# nrf9230_cellcore register map
Vendor: Nordic Semiconductor; Series: nRF92; File version: 1
CPU: CM33 r0p4, little endian, MPU, FPU, 3 interrupt priority bits, 480 interrupts, 8 SAU regions
Registers are 32-bit, read-write, reset 0x0 unless marked. A register's access mark holds for its fields unless they carry their own. Offsets are from the block's base; [hi:lo] are bit positions; lines under a group give offsets from that group; {n}, {i} and the like mark numbered series; 'fields as' and 'values as' point back to an identical list.

## SYSTEMTIMER_NS — Modem Timer/Counter 0
Base 0x44007000
Same registers: LTETIMER_NS 0x44022000, SYSTEMTIMER_S 0x54007000, LTETIMER_S 0x54022000
0x00 TASKS_START wo — Start Timer
  [0] TASKS_START
    1=Trigger task
0x04 TASKS_STOP wo — Stop Timer
  [0] TASKS_STOP
    1=Trigger task
0x08 TASKS_CLEAR wo — Clear time
  [0] TASKS_CLEAR
    1=Trigger task
0x0C TASKS_SHUTDOWN wo — Shut down timer
  [0] TASKS_SHUTDOWN
    1=Trigger task
0x10 TASKS_STANDBY wo — Timer from shutdown to stopped state
  [0] TASKS_STANDBY
    1=Trigger task
0x14 TASKS_ADJUST wo — Adjust (increment or decrement) timer count by adjustment value
  [0] TASKS_ADJUST
    1=Trigger task
{0x40+4i} TASKS_CAPTURE[{i}] (i=0..7) wo — Description collection: Capture Timer value to CC[n] register
  [0] TASKS_CAPTURE — Capture Timer value to CC[n] register
    1=Trigger task
{0x100+4i} EVENTS_COMPARE[{i}] (i=0..7) — Description collection: Compare event on CC[n] match.
  [0] EVENTS_COMPARE — Compare event on CC[n] match.
    0=NotGenerated (Event not generated); 1=Generated (Event generated)
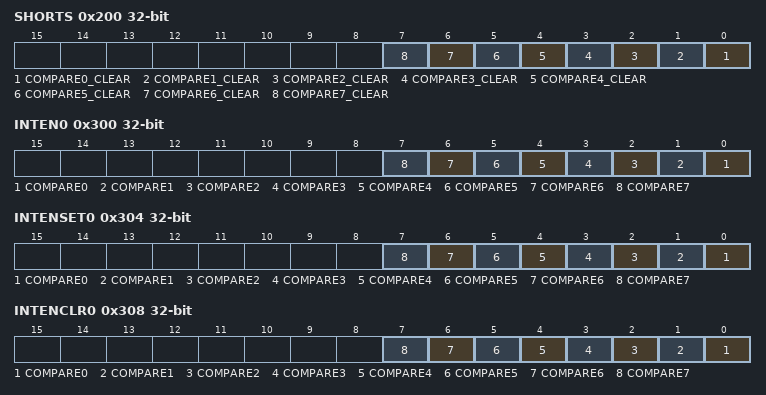
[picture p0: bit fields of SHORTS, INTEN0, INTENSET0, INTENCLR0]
0x200 SHORTS — Shortcuts between local events and tasks
  [all] fields
    0=Disabled (Disable shortcut); 1=Enabled (Enable shortcut)
  [n] COMPARE{n}_CLEAR (n=0..7) — Shortcut between event COMPARE[n] and task CLEAR
0x300 INTEN0 — Enable or disable interrupt
  [all] fields
    0=Disabled; 1=Enabled
  [n] COMPARE{n} (n=0..7) — Enable or disable interrupt for event COMPARE[{n}]
0x304 INTENSET0 — Enable interrupt
  [all] fields
    on read: 0=Disabled (Read: Disabled); 1=Enabled (Read: Enabled) | on write: 1=Set (Enable)
  [n] COMPARE{n} (n=0..7) — Write '1' to enable interrupt for event COMPARE[{n}]
0x308 INTENCLR0 — Disable interrupt
  [all] fields
    on read: 0=Disabled (Read: Disabled); 1=Enabled (Read: Enabled) | on write: 1=Clear (Disable)
  [n] COMPARE{n} (n=0..7) — Write '1' to disable interrupt for event COMPARE[{n}]
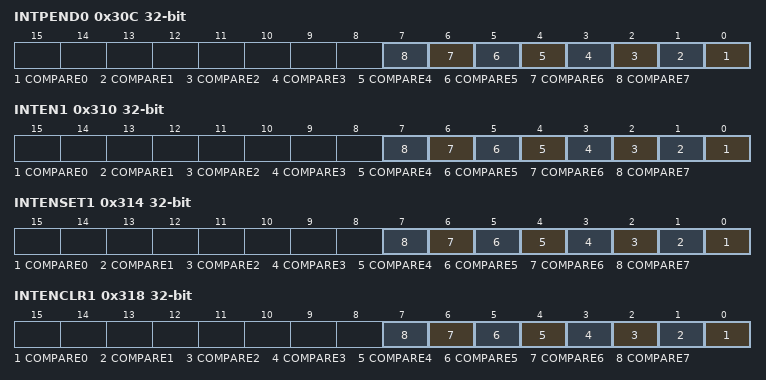
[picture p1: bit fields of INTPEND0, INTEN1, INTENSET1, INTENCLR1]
0x30C INTPEND0 ro — Pending interrupts
  [all] fields
    on read: 0=NotPending (Read: Not pending); 1=Pending (Read: Pending)
  [n] COMPARE{n} (n=0..7) — Read pending status of interrupt for event COMPARE[{n}]
0x310 INTEN1 — Enable or disable interrupt
  fields as INTEN0
0x314 INTENSET1 — Enable interrupt
  fields as INTENSET0
0x318 INTENCLR1 — Disable interrupt
  fields as INTENCLR0
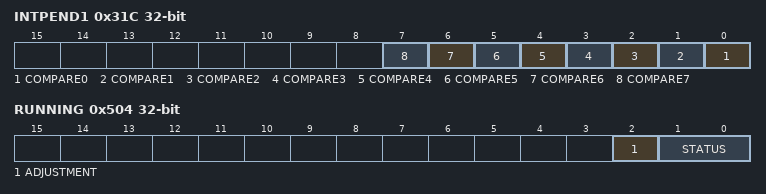
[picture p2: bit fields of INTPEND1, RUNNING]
0x31C INTPEND1 ro — Pending interrupts
  fields as INTPEND0
0x504 RUNNING ro — Status of running timer
  [2] ADJUSTMENT — Adjustment ongoing
    0=NORMAL_OPERATION (Normal operation, no events on hold.); 1=EVENTS_IN_HOLD (Compare events are on hold because of adjustment.)
  [1:0] STATUS — Current status
    0=SHUTDOWN (Timer is powered off.); 1=RUNNING (Timer is actively running.); 2=STOPPED (Timer is stopped.)
{0x540+8i} CC[{i}] (i=0..7) group — Capture/Compare register
  0x00 LO reset 0xFFFFFFFF — Description cluster: Capture/Compare register n - Low Word
    [31:0] CCLO — Capture/Compare value Low Word
  0x04 HI reset 0xFFFFFFFF — Description cluster: Capture/Compare register n - High Word
    [31:0] CCHI — Capture/Compare value High Word

## SWI0_NS — Software interrupt 0
Base 0x42058000
Same registers: SWI1_NS 0x42059000, SWI2_NS 0x4205A000, SWI3_NS 0x4205B000, SWI4_NS 0x4205C000, SWI5_NS 0x4205D000, SWI6_NS 0x4205E000, SWI7_NS 0x4205F000

## BELLBOARD_NS — BELLBOARD APB registers 0
Base 0x4F09C000
Same registers: BELLBOARD_S 0x5F09C000
{0x0+4i} TASKS_TRIGGER[{i}] (i=0..31) wo — Description collection: Task TRIGGER[n]
  [0] TASKS_TRIGGER — Task TRIGGER[n]
    1=Trigger task
{0x100+4i} EVENTS_TRIGGERED[{i}] (i=0..31) — Description collection: Event TRIGGERED[n]
  [0] EVENTS_TRIGGERED — Event TRIGGERED[n]
    0=NotGenerated (Event not generated); 1=Generated (Event generated)
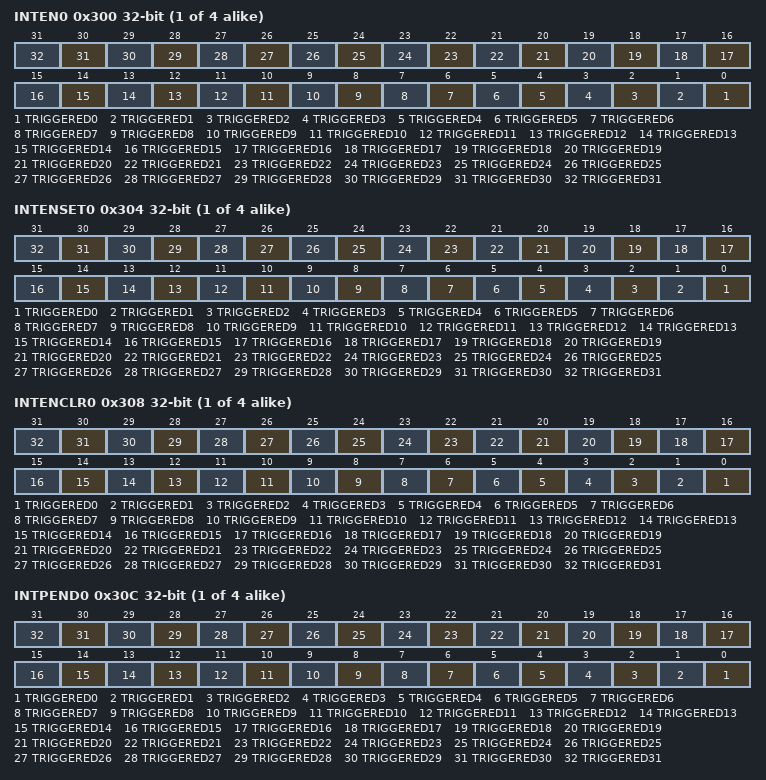
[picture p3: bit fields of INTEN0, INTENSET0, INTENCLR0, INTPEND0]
{0x300+0x10*i} INTEN{i} (i=0..3) — Enable or disable interrupt
  [all] fields
    0=Disabled; 1=Enabled
  [n] TRIGGERED{n} (n=0..31) — Enable or disable interrupt for event TRIGGERED[{n}]
{0x304+0x10*i} INTENSET{i} (i=0..3) — Enable interrupt
  [all] fields
    on read: 0=Disabled (Read: Disabled); 1=Enabled (Read: Enabled) | on write: 1=Set (Enable)
  [n] TRIGGERED{n} (n=0..31) — Write '1' to enable interrupt for event TRIGGERED[{n}]
{0x308+0x10*i} INTENCLR{i} (i=0..3) — Disable interrupt
  [all] fields
    on read: 0=Disabled (Read: Disabled); 1=Enabled (Read: Enabled) | on write: 1=Clear (Disable)
  [n] TRIGGERED{n} (n=0..31) — Write '1' to disable interrupt for event TRIGGERED[{n}]
{0x30C+0x10*i} INTPEND{i} ro (i=0..3) — Pending interrupts
  [all] fields
    on read: 0=NotPending (Read: Not pending); 1=Pending (Read: Pending)
  [n] TRIGGERED{n} (n=0..31) — Read pending status of interrupt for event TRIGGERED[{n}]
